# nrf9120_MLM1 register map
Vendor: Nordic Semiconductor; Series: nrf91; File version: 1
CPU: CM4 r0p1, little endian, MPU, FPU, 3 interrupt priority bits
Registers are 32-bit, read-write, reset 0x0 unless marked. A register's access mark holds for its fields unless they carry their own. Offsets are from the block's base; [hi:lo] are bit positions; lines under a group give offsets from that group; 'fields as' and 'values as' point back to an identical list.

## SPIM0 — Serial Peripheral Interface Master with EasyDMA 0
Base 0x40008000; alternate view of UARTE0
Same registers: SPIM1 0x40009000 (alternate view of UARTE1)
0x10 TASKS_START wo — Start SPI transaction
0x14 TASKS_STOP wo — Stop SPI transaction
0x1C TASKS_SUSPEND wo — Suspend SPI transaction
0x20 TASKS_RESUME wo — Resume SPI transaction
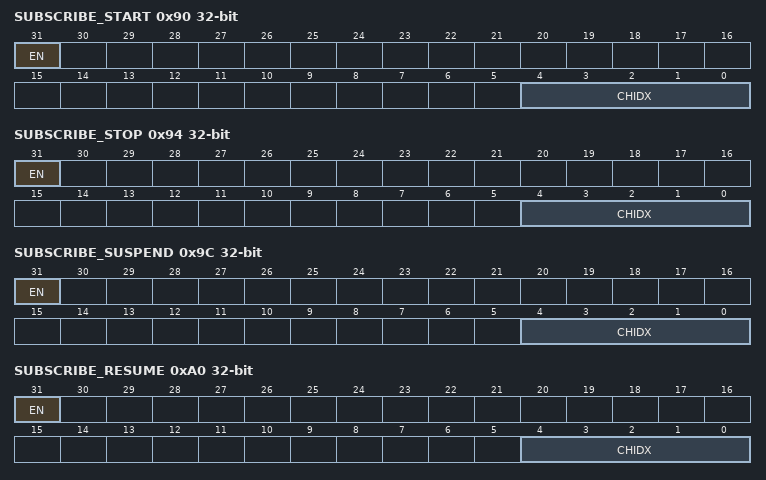
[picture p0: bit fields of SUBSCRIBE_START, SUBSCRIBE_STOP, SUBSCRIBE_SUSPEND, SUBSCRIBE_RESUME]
0x90 SUBSCRIBE_START — Subscribe configuration for TASKS_START
  [31] EN
    0=Disabled (Disable subscription); 1=Enabled (Enable subscription)
  [4:0] CHIDX — Channel the TASKS_START will subscribe to.
0x94 SUBSCRIBE_STOP — Subscribe configuration for TASKS_STOP
  [31] EN
    values as SUBSCRIBE_START.EN
  [4:0] CHIDX — Channel the TASKS_STOP will subscribe to.
0x9C SUBSCRIBE_SUSPEND — Subscribe configuration for TASKS_SUSPEND
  [31] EN
    values as SUBSCRIBE_START.EN
  [4:0] CHIDX — Channel the TASKS_SUSPEND will subscribe to.
0xA0 SUBSCRIBE_RESUME — Subscribe configuration for TASKS_RESUME
  [31] EN
    values as SUBSCRIBE_START.EN
  [4:0] CHIDX — Channel the TASKS_RESUME will subscribe to.
0x104 EVENTS_STOPPED — SPI transaction has stopped
0x110 EVENTS_ENDRX — End of RXD buffer reached
0x118 EVENTS_END — End of RXD buffer and TXD buffer reached
0x120 EVENTS_ENDTX — End of TXD buffer reached
0x14C EVENTS_STARTED — Transaction started
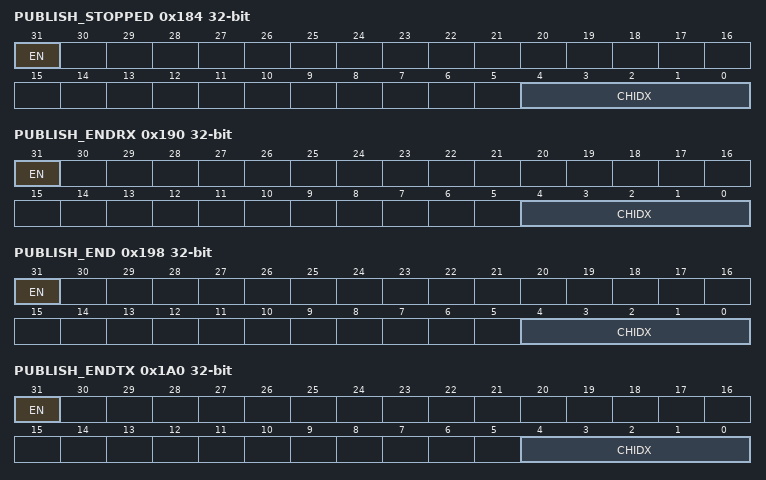
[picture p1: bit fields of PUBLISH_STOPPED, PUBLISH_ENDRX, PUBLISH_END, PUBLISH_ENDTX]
0x184 PUBLISH_STOPPED — Publish configuration for EVENTS_STOPPED
  [31] EN
    0=Disabled (Disable publishing); 1=Enabled (Enable publishing)
  [4:0] CHIDX — Channel the EVENTS_STOPPED will subscribe to.
0x190 PUBLISH_ENDRX — Publish configuration for EVENTS_ENDRX
  [31] EN
    values as PUBLISH_STOPPED.EN
  [4:0] CHIDX — Channel the EVENTS_ENDRX will subscribe to.
0x198 PUBLISH_END — Publish configuration for EVENTS_END
  [31] EN
    values as PUBLISH_STOPPED.EN
  [4:0] CHIDX — Channel the EVENTS_END will subscribe to.
0x1A0 PUBLISH_ENDTX — Publish configuration for EVENTS_ENDTX
  [31] EN
    values as PUBLISH_STOPPED.EN
  [4:0] CHIDX — Channel the EVENTS_ENDTX will subscribe to.
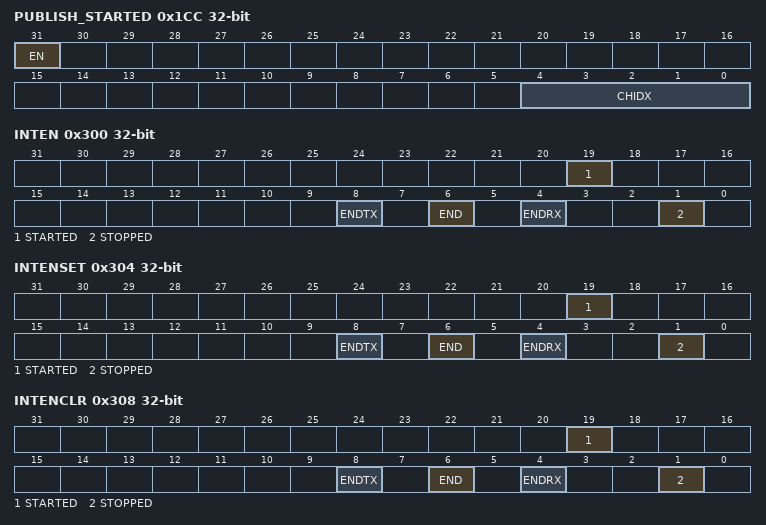
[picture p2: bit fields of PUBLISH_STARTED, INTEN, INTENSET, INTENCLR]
0x1CC PUBLISH_STARTED — Publish configuration for EVENTS_STARTED
  [31] EN
    values as PUBLISH_STOPPED.EN
  [4:0] CHIDX — Channel the EVENTS_STARTED will subscribe to.
0x200 SHORTS — Shortcut register
  [17] END_START — Shortcut between END event and START task
    0=Disabled (Disable shortcut); 1=Enabled (Enable shortcut)
0x300 INTEN — Enable or disable interrupt
  [all] fields
    0=Disabled; 1=Enabled
  [19] STARTED — Enable or disable interrupt for STARTED event
  [8] ENDTX — Enable or disable interrupt for ENDTX event
  [6] END — Enable or disable interrupt for END event
  [4] ENDRX — Enable or disable interrupt for ENDRX event
  [1] STOPPED — Enable or disable interrupt for STOPPED event
0x304 INTENSET — Enable interrupt
  [all] fields
    on read: 0=Disabled (Read: Disabled); 1=Enabled (Read: Enabled) | on write: 1=Set (Enable)
  [19] STARTED — Write '1' to Enable interrupt for STARTED event
  [8] ENDTX — Write '1' to Enable interrupt for ENDTX event
  [6] END — Write '1' to Enable interrupt for END event
  [4] ENDRX — Write '1' to Enable interrupt for ENDRX event
  [1] STOPPED — Write '1' to Enable interrupt for STOPPED event
0x308 INTENCLR — Disable interrupt
  [all] fields
    on read: 0=Disabled (Read: Disabled); 1=Enabled (Read: Enabled) | on write: 1=Clear (Disable)
  [19] STARTED — Write '1' to Disable interrupt for STARTED event
  [8] ENDTX — Write '1' to Disable interrupt for ENDTX event
  [6] END — Write '1' to Disable interrupt for END event
  [4] ENDRX — Write '1' to Disable interrupt for ENDRX event
  [1] STOPPED — Write '1' to Disable interrupt for STOPPED event
0x500 ENABLE — Enable SPIM
  [3:0] ENABLE — Enable or disable SPIM
    0=Disabled (Disable SPIM); 7=Enabled (Enable SPIM)
0x508 PSEL group — Unspecified
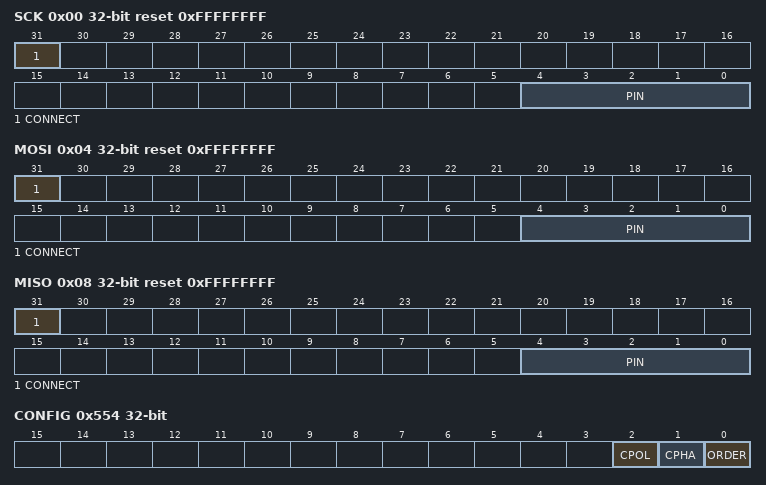
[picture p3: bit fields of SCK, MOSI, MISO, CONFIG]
  0x00 SCK reset 0xFFFFFFFF — Pin select for SCK
    [31] CONNECT — Connection
      1=Disconnected; 0=Connected
    [4:0] PIN — Pin number
  0x04 MOSI reset 0xFFFFFFFF — Pin select for MOSI signal
    fields as PSEL.SCK
  0x08 MISO reset 0xFFFFFFFF — Pin select for MISO signal
    fields as PSEL.SCK
0x518 RXDDATA ro — RXD register
  [7:0] RXD — RX data received. Double buffered.
0x51C TXDDATA — TXD register
  [7:0] TXD — TX data to send. Double buffered.
0x524 FREQUENCY reset 0x4000000 — SPI frequency
  [31:0] FREQUENCY — SPI master data rate
    0x2000000=K125 (125 kbps); 0x4000000=K250 (250 kbps); 0x8000000=K500 (500 kbps); 0x10000000=M1 (1 Mbps); 0x20000000=M2 (2 Mbps); 0x40000000=M4 (4 Mbps); 0x80000000=M8 (8 Mbps)
0x534 RXD group — RXD EasyDMA channel
  0x00 PTR — Data pointer
  0x04 MAXCNT — Maximum number of bytes in receive buffer
    [7:0] MAXCNT
  0x08 AMOUNT ro — Number of bytes transferred in the last transaction
    [7:0] AMOUNT
  0x0C LIST — EasyDMA list type
    [2:0] LIST — List type
      0=Disabled (Disable EasyDMA list); 1=ArrayList (Use array list)
0x544 TXD group — TXD EasyDMA channel
  0x00 PTR — Data pointer
  0x04 MAXCNT — Maximum number of bytes in transmit buffer
    [7:0] MAXCNT
  0x08 AMOUNT ro — Number of bytes transferred in the last transaction
    [7:0] AMOUNT
  0x0C LIST — EasyDMA list type
    fields as RXD.LIST
0x554 CONFIG — Configuration register
  [2] CPOL — Serial clock (SCK) polarity
    0=ActiveHigh; 1=ActiveLow
  [1] CPHA — Serial clock (SCK) phase
    0=Leading (Sample on leading edge of clock, shift serial data on trailing edge); 1=Trailing (Sample on trailing edge of clock, shift serial data on leading edge)
  [0] ORDER — Bit order
    0=MsbFirst (Most significant bit shifted out first); 1=LsbFirst (Least significant bit shifted out first)
0x5C0 ORC — Over-read character. Character clocked out in case and over-read of the TXD buffer.
  [7:0] ORC
0xFFC POWER reset 0x1 — Peripheral power control
  [0] POWER — Peripheral power control. The peripheral and its registers will be reset to its initial state by switching the peripheral off and then back on again.
    0=Disabled (Peripheral is powered off); 1=Enabled (Peripheral is powered on)
